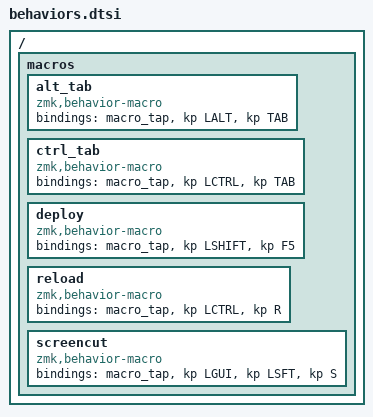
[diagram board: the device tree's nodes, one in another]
/ {
    macros {
        alt_tab: alt_tab {
            compatible = "zmk,behavior-macro";

            bindings = <&macro_tap &kp LALT &kp TAB>;
        };

        ctrl_tab: ctrl_tab {
            compatible = "zmk,behavior-macro";

            bindings = <&macro_tap &kp LCTRL &kp TAB>;
        };

        deploy: deploy {
            compatible = "zmk,behavior-macro";

            bindings = <&macro_tap &kp LSHIFT &kp F5>;
        };

        reload: reload {
            compatible = "zmk,behavior-macro";

            bindings = <&macro_tap &kp LCTRL &kp R>;
        };

         screencut: screencut {
            compatible = "zmk,behavior-macro";

            bindings = <&macro_tap &kp LGUI &kp LSFT &kp S>;
        };
    };
};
